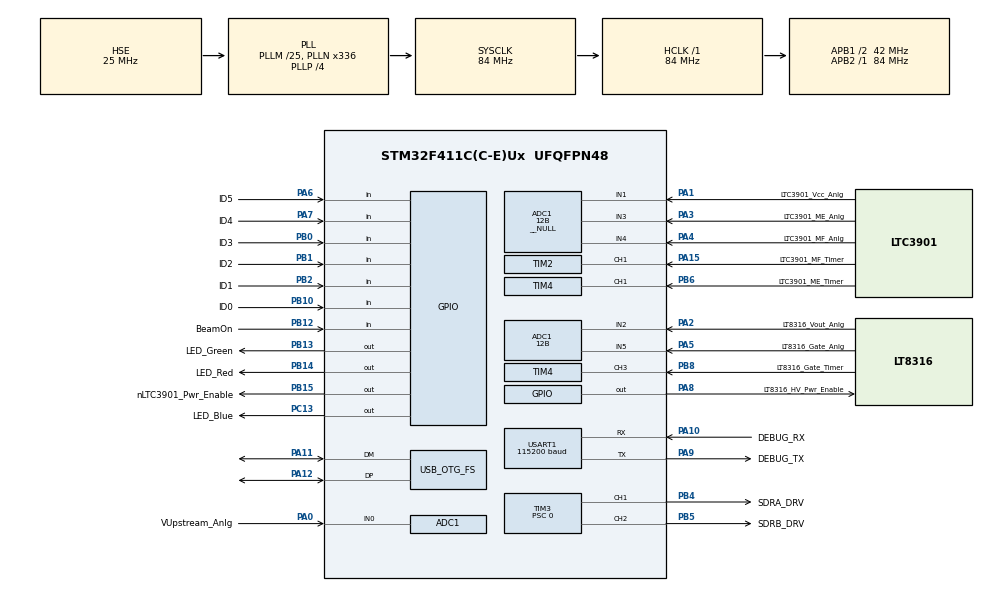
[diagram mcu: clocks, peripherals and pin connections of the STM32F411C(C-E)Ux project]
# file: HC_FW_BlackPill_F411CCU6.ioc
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ADC1.Channel-0\#ChannelRegularConversion=ADC_CHANNEL_0
ADC1.Channel-1\#ChannelRegularConversion=ADC_CHANNEL_1
ADC1.Channel-2\#ChannelRegularConversion=ADC_CHANNEL_2
ADC1.Channel-3\#ChannelRegularConversion=ADC_CHANNEL_3
ADC1.Channel-4\#ChannelRegularConversion=ADC_CHANNEL_4
ADC1.Channel-5\#ChannelRegularConversion=ADC_CHANNEL_5
ADC1.Channel-IN=ADC_CHANNEL_VREFINT
ADC1.Channel-IN0=ADC_CHANNEL_0
ADC1.Channel-IN1=ADC_CHANNEL_1
ADC1.Channel-IN2=ADC_CHANNEL_2
ADC1.Channel-IN3=ADC_CHANNEL_3
ADC1.Channel-IN4=ADC_CHANNEL_4
ADC1.Channel-IN5=ADC_CHANNEL_5
ADC1.ClockPrescaler=ADC_CLOCK_SYNC_PCLK_DIV8
ADC1.ContinuousConvMode=ENABLE
ADC1.DMAContinuousRequests=DISABLE
ADC1.DataAlign=ADC_DATAALIGN_RIGHT
ADC1.DiscontinuousConvMode=DISABLE
ADC1.EOCSelection=ADC_EOC_SEQ_CONV
ADC1.EnableAnalogWatchDog=false
ADC1.ExternalTrigConv=ADC_SOFTWARE_START
ADC1.ExternalTrigConvEdge=ADC_EXTERNALTRIGCONVEDGE_NONE
ADC1.InjNumberOfConversion=0
ADC1.Mode=__NULL
ADC1.NbrOfConversion=8
ADC1.Rank-0\#ChannelRegularConversion=1
ADC1.Rank-1\#ChannelRegularConversion=2
ADC1.Rank-2\#ChannelRegularConversion=3
ADC1.Rank-3\#ChannelRegularConversion=4
ADC1.Rank-4\#ChannelRegularConversion=5
ADC1.Rank-5\#ChannelRegularConversion=6
ADC1.Rank-6\#ChannelRegularConversion=7
ADC1.Rank-7\#ChannelRegularConversion=8
ADC1.Resolution=ADC_RESOLUTION_12B
ADC1.SamplingTime-0\#ChannelRegularConversion=ADC_SAMPLETIME_15CYCLES
ADC1.SamplingTime-1\#ChannelRegularConversion=ADC_SAMPLETIME_15CYCLES
ADC1.SamplingTime-2\#ChannelRegularConversion=ADC_SAMPLETIME_15CYCLES
ADC1.SamplingTime-3\#ChannelRegularConversion=ADC_SAMPLETIME_15CYCLES
ADC1.SamplingTime-4\#ChannelRegularConversion=ADC_SAMPLETIME_15CYCLES
ADC1.SamplingTime-5\#ChannelRegularConversion=ADC_SAMPLETIME_15CYCLES
ADC1.SamplingTime-6\#ChannelRegularConversion=ADC_SAMPLETIME_15CYCLES
ADC1.SamplingTime-7\#ChannelRegularConversion=ADC_SAMPLETIME_15CYCLES
ADC1.ScanConvMode=ENABLE
ADC1.master=1
Dma.ADC1.0.Direction=DMA_PERIPH_TO_MEMORY
Dma.ADC1.0.FIFOMode=DMA_FIFOMODE_ENABLE
Dma.ADC1.0.FIFOThreshold=DMA_FIFO_THRESHOLD_FULL
Dma.ADC1.0.Instance=DMA2_Stream0
Dma.ADC1.0.MemBurst=DMA_MBURST_SINGLE
Dma.ADC1.0.MemDataAlignment=DMA_MDATAALIGN_HALFWORD
Dma.ADC1.0.MemInc=DMA_MINC_ENABLE
Dma.ADC1.0.Mode=DMA_NORMAL
Dma.ADC1.0.PeriphBurst=DMA_PBURST_SINGLE
Dma.ADC1.0.PeriphDataAlignment=DMA_PDATAALIGN_HALFWORD
Dma.ADC1.0.PeriphInc=DMA_PINC_DISABLE
Dma.ADC1.0.Priority=DMA_PRIORITY_LOW
Dma.Request0=ADC1
Dma.Request1=TIM4_CH3
Dma.Request2=TIM4_CH1
Dma.Request3=TIM4_CH2
Dma.Request4=USART1_RX
Dma.Request5=TIM2_CH1
Dma.Request6=TIM2_CH2/CH4
Dma.TIM2_CH1.5.Direction=DMA_PERIPH_TO_MEMORY
Dma.TIM2_CH1.5.FIFOMode=DMA_FIFOMODE_ENABLE
Dma.TIM2_CH1.5.FIFOThreshold=DMA_FIFO_THRESHOLD_FULL
Dma.TIM2_CH1.5.Instance=DMA1_Stream5
Dma.TIM2_CH1.5.MemBurst=DMA_MBURST_SINGLE
Dma.TIM2_CH1.5.MemDataAlignment=DMA_MDATAALIGN_WORD
Dma.TIM2_CH1.5.MemInc=DMA_MINC_ENABLE
Dma.TIM2_CH1.5.Mode=DMA_NORMAL
Dma.TIM2_CH1.5.PeriphBurst=DMA_PBURST_SINGLE
Dma.TIM2_CH1.5.PeriphDataAlignment=DMA_PDATAALIGN_WORD
Dma.TIM2_CH1.5.PeriphInc=DMA_PINC_DISABLE
Dma.TIM2_CH1.5.Priority=DMA_PRIORITY_LOW
Dma.TIM2_CH2/CH4.6.Direction=DMA_PERIPH_TO_MEMORY
Dma.TIM2_CH2/CH4.6.FIFOMode=DMA_FIFOMODE_ENABLE
Dma.TIM2_CH2/CH4.6.FIFOThreshold=DMA_FIFO_THRESHOLD_FULL
Dma.TIM2_CH2/CH4.6.Instance=DMA1_Stream6
Dma.TIM2_CH2/CH4.6.MemBurst=DMA_MBURST_SINGLE
Dma.TIM2_CH2/CH4.6.MemDataAlignment=DMA_MDATAALIGN_WORD
Dma.TIM2_CH2/CH4.6.MemInc=DMA_MINC_ENABLE
Dma.TIM2_CH2/CH4.6.Mode=DMA_NORMAL
Dma.TIM2_CH2/CH4.6.PeriphBurst=DMA_PBURST_SINGLE
Dma.TIM2_CH2/CH4.6.PeriphDataAlignment=DMA_PDATAALIGN_WORD
Dma.TIM2_CH2/CH4.6.PeriphInc=DMA_PINC_DISABLE
Dma.TIM2_CH2/CH4.6.Priority=DMA_PRIORITY_LOW
Dma.TIM4_CH1.2.Direction=DMA_PERIPH_TO_MEMORY
Dma.TIM4_CH1.2.FIFOMode=DMA_FIFOMODE_ENABLE
Dma.TIM4_CH1.2.FIFOThreshold=DMA_FIFO_THRESHOLD_FULL
Dma.TIM4_CH1.2.Instance=DMA1_Stream0
Dma.TIM4_CH1.2.MemBurst=DMA_MBURST_SINGLE
Dma.TIM4_CH1.2.MemDataAlignment=DMA_MDATAALIGN_HALFWORD
Dma.TIM4_CH1.2.MemInc=DMA_MINC_ENABLE
Dma.TIM4_CH1.2.Mode=DMA_NORMAL
Dma.TIM4_CH1.2.PeriphBurst=DMA_PBURST_SINGLE
Dma.TIM4_CH1.2.PeriphDataAlignment=DMA_PDATAALIGN_HALFWORD
Dma.TIM4_CH1.2.PeriphInc=DMA_PINC_DISABLE
Dma.TIM4_CH1.2.Priority=DMA_PRIORITY_LOW
Dma.TIM4_CH2.3.Direction=DMA_PERIPH_TO_MEMORY
Dma.TIM4_CH2.3.FIFOMode=DMA_FIFOMODE_ENABLE
Dma.TIM4_CH2.3.FIFOThreshold=DMA_FIFO_THRESHOLD_FULL
Dma.TIM4_CH2.3.Instance=DMA1_Stream3
Dma.TIM4_CH2.3.MemBurst=DMA_MBURST_SINGLE
Dma.TIM4_CH2.3.MemDataAlignment=DMA_MDATAALIGN_HALFWORD
Dma.TIM4_CH2.3.MemInc=DMA_MINC_ENABLE
Dma.TIM4_CH2.3.Mode=DMA_NORMAL
Dma.TIM4_CH2.3.PeriphBurst=DMA_PBURST_SINGLE
Dma.TIM4_CH2.3.PeriphDataAlignment=DMA_PDATAALIGN_HALFWORD
Dma.TIM4_CH2.3.PeriphInc=DMA_PINC_DISABLE
Dma.TIM4_CH2.3.Priority=DMA_PRIORITY_LOW
Dma.TIM4_CH3.1.Direction=DMA_PERIPH_TO_MEMORY
Dma.TIM4_CH3.1.FIFOMode=DMA_FIFOMODE_ENABLE
Dma.TIM4_CH3.1.FIFOThreshold=DMA_FIFO_THRESHOLD_FULL
Dma.TIM4_CH3.1.Instance=DMA1_Stream7
Dma.TIM4_CH3.1.MemBurst=DMA_MBURST_SINGLE
Dma.TIM4_CH3.1.MemDataAlignment=DMA_MDATAALIGN_HALFWORD
Dma.TIM4_CH3.1.MemInc=DMA_MINC_ENABLE
Dma.TIM4_CH3.1.Mode=DMA_NORMAL
Dma.TIM4_CH3.1.PeriphBurst=DMA_PBURST_SINGLE
Dma.TIM4_CH3.1.PeriphDataAlignment=DMA_PDATAALIGN_HALFWORD
Dma.TIM4_CH3.1.PeriphInc=DMA_PINC_DISABLE
Dma.TIM4_CH3.1.Priority=DMA_PRIORITY_LOW
Dma.USART1_RX.4.Direction=DMA_PERIPH_TO_MEMORY
Dma.USART1_RX.4.FIFOMode=DMA_FIFOMODE_DISABLE
Dma.USART1_RX.4.Instance=DMA2_Stream2
Dma.USART1_RX.4.MemDataAlignment=DMA_MDATAALIGN_BYTE
Dma.USART1_RX.4.MemInc=DMA_MINC_ENABLE
Dma.USART1_RX.4.Mode=DMA_CIRCULAR
Dma.USART1_RX.4.PeriphDataAlignment=DMA_PDATAALIGN_BYTE
Dma.USART1_RX.4.PeriphInc=DMA_PINC_DISABLE
Dma.USART1_RX.4.Priority=DMA_PRIORITY_LOW
Mcu.Family=STM32F4
Mcu.Name=STM32F411C(C-E)Ux
Mcu.Package=UFQFPN48
NVIC.DMA1_Stream0_IRQn=true\:0\:0\:false\:false\:true\:false\:true\:true
NVIC.DMA1_Stream3_IRQn=true\:0\:0\:false\:false\:true\:false\:true\:true
NVIC.DMA1_Stream5_IRQn=true\:0\:0\:false\:false\:true\:false\:true\:true
NVIC.DMA1_Stream6_IRQn=true\:0\:0\:false\:false\:true\:false\:true\:true
NVIC.DMA1_Stream7_IRQn=true\:0\:0\:false\:false\:true\:false\:true\:true
NVIC.DMA2_Stream0_IRQn=true\:0\:0\:false\:false\:true\:false\:true\:true
NVIC.DMA2_Stream2_IRQn=true\:0\:0\:false\:false\:true\:false\:true\:true
NVIC.OTG_FS_IRQn=true\:0\:0\:false\:false\:true\:false\:true\:true
NVIC.PriorityGroup=NVIC_PRIORITYGROUP_4
NVIC.USART1_IRQn=true\:0\:0\:false\:false\:true\:true\:true\:true
PA0-WKUP.GPIO_Label=VUpstream_Anlg
PA0-WKUP.Signal=ADCx_IN0
PA1.GPIO_Label=LTC3901_Vcc_Anlg
PA1.Signal=ADCx_IN1
PA10.GPIO_Label=DEBUG_RX
PA10.Mode=Asynchronous
PA10.Signal=USART1_RX
PA11.Mode=Device_Only
PA11.Signal=USB_OTG_FS_DM
PA12.Mode=Device_Only
PA12.Signal=USB_OTG_FS_DP
PA13.Mode=Serial_Wire
PA13.Signal=SYS_JTMS-SWDIO
PA14.Mode=Serial_Wire
PA14.Signal=SYS_JTCK-SWCLK
PA15.GPIO_Label=LTC3901_MF_Timer
PA15.Signal=S_TIM2_CH1_ETR
PA2.GPIO_Label=LT8316_Vout_Anlg
PA2.Signal=ADCx_IN2
PA3.GPIO_Label=LTC3901_ME_Anlg
PA3.Signal=ADCx_IN3
PA4.GPIO_Label=LTC3901_MF_Anlg
PA4.Signal=ADCx_IN4
PA5.GPIO_Label=LT8316_Gate_Anlg
PA5.Signal=ADCx_IN5
PA6.GPIO_Label=ID5
PA6.Signal=GPIO_Input
PA7.GPIO_Label=ID4
PA7.Signal=GPIO_Input
PA8.GPIO_Label=LT8316_HV_Pwr_Enable
PA8.PinState=GPIO_PIN_RESET
PA8.Signal=GPIO_Output
PA9.GPIO_Label=DEBUG_TX
PA9.Mode=Asynchronous
PA9.Signal=USART1_TX
PB0.GPIO_Label=ID3
PB0.Signal=GPIO_Input
PB1.GPIO_Label=ID2
PB1.Signal=GPIO_Input
PB10.GPIO_Label=ID0
PB10.Signal=GPIO_Input
PB12.GPIO_Label=BeamOn
PB12.GPIO_PuPd=GPIO_PULLDOWN
PB12.Signal=GPIO_Input
PB13.GPIO_Label=LED_Green
PB13.PinState=GPIO_PIN_SET
PB13.Signal=GPIO_Output
PB14.GPIO_Label=LED_Red
PB14.PinState=GPIO_PIN_SET
PB14.Signal=GPIO_Output
PB15.GPIO_Label=nLTC3901_Pwr_Enable
PB15.PinState=GPIO_PIN_SET
PB15.Signal=GPIO_Output
PB2.GPIO_Label=ID1
PB2.Signal=GPIO_Input
PB4.GPIO_Label=SDRA_DRV
PB4.GPIO_Speed=GPIO_SPEED_FREQ_VERY_HIGH
PB4.Signal=S_TIM3_CH1
PB5.GPIO_Label=SDRB_DRV
PB5.Signal=S_TIM3_CH2
PB6.GPIO_Label=LTC3901_ME_Timer
PB6.Signal=S_TIM4_CH1
PB8.GPIO_Label=LT8316_Gate_Timer
PB8.Signal=S_TIM4_CH3
PC13-ANTI_TAMP.GPIO_Label=LED_Blue
PC13-ANTI_TAMP.PinState=GPIO_PIN_SET
PC13-ANTI_TAMP.Signal=GPIO_Output
PC14-OSC32_IN.Mode=LSE-External-Oscillator
PC14-OSC32_IN.Signal=RCC_OSC32_IN
PC15-OSC32_OUT.Mode=LSE-External-Oscillator
PC15-OSC32_OUT.Signal=RCC_OSC32_OUT
PH0\ -\ OSC_IN.Mode=HSE-External-Oscillator
PH0\ -\ OSC_IN.Signal=RCC_OSC_IN
PH1\ -\ OSC_OUT.Mode=HSE-External-Oscillator
PH1\ -\ OSC_OUT.Signal=RCC_OSC_OUT
ProjectManager.HeapSize=0x200
ProjectManager.StackSize=0x400
ProjectManager.TargetToolchain=CMake
RCC.48MHZClocksFreq_Value=48000000
RCC.AHBFreq_Value=84000000
RCC.APB1CLKDivider=RCC_HCLK_DIV2
RCC.APB1Freq_Value=42000000
RCC.APB1TimFreq_Value=84000000
RCC.APB2Freq_Value=84000000
RCC.APB2TimFreq_Value=84000000
RCC.CortexFreq_Value=84000000
RCC.FLatency=FLASH_LATENCY_2
RCC.HCLKFreq_Value=84000000
RCC.HSE_VALUE=25000000
RCC.HSI_VALUE=16000000
RCC.PLLM=25
RCC.PLLN=336
RCC.PLLP=RCC_PLLP_DIV4
RCC.PLLQ=7
RCC.PWR_Regulator_Voltage_Scale=PWR_REGULATOR_VOLTAGE_SCALE2
RCC.SYSCLKFreq_VALUE=84000000
RCC.SYSCLKSource=RCC_SYSCLKSOURCE_PLLCLK
RCC.VCOOutputFreq_Value=336000000
RTC.AsynchPrediv=127
RTC.Date=2
RTC.DayLightSaving=RTC_DAYLIGHTSAVING_NONE
RTC.Format=RTC_FORMAT_BIN
RTC.HourFormat=RTC_HOURFORMAT_24
RTC.Hours=5
RTC.Minutes=17
RTC.Month=RTC_MONTH_MAY
RTC.Seconds=0
RTC.StoreOperation=RTC_STOREOPERATION_RESET
RTC.SynchPrediv=255
RTC.WeekDay=RTC_WEEKDAY_SATURDAY
RTC.Year=0
SH.ADCx_IN0.0=ADC1_IN0,IN0
SH.ADCx_IN1.0=ADC1_IN1,IN1
SH.ADCx_IN2.0=ADC1_IN2,IN2
SH.ADCx_IN3.0=ADC1_IN3,IN3
SH.ADCx_IN4.0=ADC1_IN4,IN4
SH.ADCx_IN5.0=ADC1_IN5,IN5
SH.S_TIM2_CH1_ETR.0=TIM2_CH1,Input_Capture1_from_TI1
SH.S_TIM3_CH1.0=TIM3_CH1,Output Compare1 CH1
SH.S_TIM3_CH2.0=TIM3_CH2,Output Compare2 CH2
SH.S_TIM4_CH1.0=TIM4_CH1,Input_Capture1_from_TI1
SH.S_TIM4_CH3.0=TIM4_CH3,Input_Capture3_from_TI3
TIM2.AutoReloadPreload=TIM_AUTORELOAD_PRELOAD_DISABLE
TIM2.Channel-Input_Capture1_from_TI1=TIM_CHANNEL_1
TIM2.Channel-Input_Capture2_from_TI1_63=TIM_CHANNEL_2
TIM2.ClockDivision=TIM_CLOCKDIVISION_DIV1
TIM2.CounterMode=TIM_COUNTERMODE_UP
TIM2.ICFilter_CH1=0
TIM2.ICPolarity_CH1=TIM_INPUTCHANNELPOLARITY_RISING
TIM2.ICPolarity_CH2=TIM_INPUTCHANNELPOLARITY_FALLING
TIM2.ICPrescaler-Input_Capture1_from_TI1=TIM_ICPSC_DIV1
TIM2.ICPrescaler-Input_Capture2_from_TI1_63=TIM_ICPSC_DIV1
TIM2.ICSelection-Input_Capture1_from_TI1=TIM_ICSELECTION_DIRECTTI
TIM2.ICSelection-Input_Capture2_from_TI1_63=TIM_ICSELECTION_INDIRECTTI
TIM2.Period=4294967295
TIM2.Prescaler=7
TIM2.TIM_MasterOutputTrigger=TIM_TRGO_RESET
TIM2.TIM_MasterSlaveMode=TIM_MASTERSLAVEMODE_DISABLE
TIM3.AutoReloadPreload=TIM_AUTORELOAD_PRELOAD_ENABLE
TIM3.Channel-Output\ Compare1\ CH1=TIM_CHANNEL_1
TIM3.Channel-Output\ Compare2\ CH2=TIM_CHANNEL_2
TIM3.ClockDivision=TIM_CLOCKDIVISION_DIV1
TIM3.CounterMode=TIM_COUNTERMODE_UP
TIM3.OC1Preload=ENABLE
TIM3.OC2Preload=ENABLE
TIM3.OCMode_1=TIM_OCMODE_TOGGLE
TIM3.OCMode_2=TIM_OCMODE_TOGGLE
TIM3.OCPolarity_1=TIM_OCPOLARITY_HIGH
TIM3.OCPolarity_2=TIM_OCPOLARITY_HIGH
TIM3.Period=167
TIM3.Prescaler=0
TIM3.Pulse-Output\ Compare1\ CH1=0
TIM3.Pulse-Output\ Compare2\ CH2=83
TIM3.TIM_MasterOutputTrigger=TIM_TRGO_RESET
TIM3.TIM_MasterSlaveMode=TIM_MASTERSLAVEMODE_DISABLE
TIM4.AutoReloadPreload=TIM_AUTORELOAD_PRELOAD_DISABLE
TIM4.Channel-Input_Capture1_from_TI1=TIM_CHANNEL_1
TIM4.Channel-Input_Capture2_from_TI1_63=TIM_CHANNEL_2
TIM4.Channel-Input_Capture3_from_TI3=TIM_CHANNEL_3
TIM4.Channel-Input_Capture4_from_TI3_63=TIM_CHANNEL_4
TIM4.ClockDivision=TIM_CLOCKDIVISION_DIV1
TIM4.CounterMode=TIM_COUNTERMODE_UP
TIM4.ICFilter_CH1=0
TIM4.ICFilter_CH3=0
TIM4.ICPolarity_CH1=TIM_INPUTCHANNELPOLARITY_RISING
TIM4.ICPolarity_CH2=TIM_INPUTCHANNELPOLARITY_FALLING
TIM4.ICPolarity_CH3=TIM_INPUTCHANNELPOLARITY_RISING
TIM4.ICPolarity_CH4=TIM_INPUTCHANNELPOLARITY_FALLING
TIM4.ICPrescaler-Input_Capture1_from_TI1=TIM_ICPSC_DIV1
TIM4.ICPrescaler-Input_Capture2_from_TI1_63=TIM_ICPSC_DIV1
TIM4.ICPrescaler-Input_Capture3_from_TI3=TIM_ICPSC_DIV1
TIM4.ICPrescaler-Input_Capture4_from_TI3_63=TIM_ICPSC_DIV1
TIM4.ICSelection-Input_Capture1_from_TI1=TIM_ICSELECTION_DIRECTTI
TIM4.ICSelection-Input_Capture2_from_TI1_63=TIM_ICSELECTION_INDIRECTTI
TIM4.ICSelection-Input_Capture3_from_TI3=TIM_ICSELECTION_DIRECTTI
TIM4.ICSelection-Input_Capture4_from_TI3_63=TIM_ICSELECTION_INDIRECTTI
TIM4.Period=65535
TIM4.Prescaler=7
TIM4.TIM_MasterOutputTrigger=TIM_TRGO_RESET
TIM4.TIM_MasterSlaveMode=TIM_MASTERSLAVEMODE_DISABLE
TIM5.AutoReloadPreload=TIM_AUTORELOAD_PRELOAD_DISABLE
TIM5.ClockDivision=TIM_CLOCKDIVISION_DIV1
TIM5.CounterMode=TIM_COUNTERMODE_UP
TIM5.Period=4294967295
TIM5.Prescaler=0
TIM5.TIM_MasterOutputTrigger=TIM_TRGO_RESET
TIM5.TIM_MasterSlaveMode=TIM_MASTERSLAVEMODE_DISABLE
USART1.BaudRate=115200
USART1.Mode=MODE_TX_RX
USART1.OverSampling=UART_OVERSAMPLING_16
USART1.Parity=PARITY_NONE
USART1.StopBits=STOPBITS_1
USART1.VirtualMode=VM_ASYNC
USART1.WordLength=WORDLENGTH_8B
USB_DEVICE.APP_RX_DATA_SIZE=1024
USB_DEVICE.APP_TX_DATA_SIZE=1024
USB_DEVICE.CLASS_NAME_FS=CDC
USB_DEVICE.CONFIGURATION_STRING_CDC_FS=CDC Config
USB_DEVICE.INTERFACE_STRING_CDC_FS=CDC Interface
USB_DEVICE.LANGID_STRING=1033
USB_DEVICE.MANUFACTURER_STRING=STMicroelectronics
USB_DEVICE.PID_CDC_FS=22336
USB_DEVICE.PRODUCT_STRING_CDC_FS=STM32 Virtual ComPort
USB_DEVICE.USBD_DEBUG_LEVEL=0
USB_DEVICE.USBD_MAX_NUM_CONFIGURATION=1
USB_DEVICE.USBD_MAX_NUM_INTERFACES=1
USB_DEVICE.USBD_MAX_STR_DESC_SIZ=512
USB_DEVICE.USBD_SELF_POWERED=1
USB_DEVICE.VID=1155
USB_DEVICE.VirtualMode=Cdc
USB_DEVICE.VirtualModeFS=Cdc_FS
USB_OTG_FS.Sof_enable=DISABLE
USB_OTG_FS.VirtualMode=Device_Only
USB_OTG_FS.low_power_enable=DISABLE
USB_OTG_FS.lpm_enable=DISABLE
USB_OTG_FS.vbus_sensing_enable=DISABLE
VP_ADC1_TempSens_Input.Mode=IN-TempSens
VP_ADC1_Vref_Input.Mode=IN-Vrefint
VP_RTC_VS_RTC_Activate.Mode=RTC_Enabled
VP_RTC_VS_RTC_Calendar.Mode=RTC_Calendar
VP_TIM2_VS_ClockSourceINT.Mode=Internal
VP_TIM2_VS_indirect_ch1.Mode=Input_Capture2_from_TI1_63
VP_TIM3_VS_ClockSourceINT.Mode=Internal
VP_TIM4_VS_indirect_ch1.Mode=Input_Capture2_from_TI1_63
VP_TIM4_VS_indirect_ch3.Mode=Input_Capture4_from_TI3_63
VP_TIM5_VS_ClockSourceINT.Mode=Internal
VP_USB_DEVICE_VS_USB_DEVICE_CDC_FS.Mode=CDC_FS
board=custom

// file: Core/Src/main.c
/* USER CODE BEGIN Header */
/**
  ******************************************************************************
  * @file           : main.c
  * @brief          : Main program body
  ******************************************************************************
  * @attention
  *
  * Copyright (c) 2026 STMicroelectronics.
  * All rights reserved.
  *
  * This software is licensed under terms that can be found in the LICENSE file
  * in the root directory of this software component.
  * If no LICENSE file comes with this software, it is provided AS-IS.
  *
  ******************************************************************************
  */
/* USER CODE END Header */
#include "main.h"
#include "adc.h"
#include "dma.h"
#include "rtc.h"
#include "tim.h"
#include "usart.h"
#include "usb_device.h"
#include "gpio.h"

/* USER CODE BEGIN Includes */
#include "fw_app.h"
#include "reset_reason_drv.h"
#include "usbd_cdc_if.h"
/* USER CODE END Includes */

void SystemClock_Config(void);

int main(void)
{

  /* MCU Configuration--------------------------------------------------------*/

  /* Reset of all peripherals, Initializes the Flash interface and the Systick. */
  HAL_Init();

  /* USER CODE BEGIN Init */
  reset_reason_drv_init();

  /* USER CODE END Init */

  /* Configure the system clock */
  SystemClock_Config();

  /* Initialize all configured peripherals */
  MX_GPIO_Init();
  MX_DMA_Init();
  MX_ADC1_Init();
  MX_TIM2_Init();
  MX_TIM3_Init();
  MX_TIM4_Init();
  MX_USART1_UART_Init();
  MX_USB_DEVICE_Init();
  MX_TIM5_Init();
  MX_RTC_Init();
  /* USER CODE BEGIN 2 */
  fw_app_init();

//  sync_drv_enable();

//  sync_drv_configure_and_enable(&sync_cfg);

//  HAL_TIM_OC_Start(&htim3, TIM_CHANNEL_1);
//  HAL_TIM_OC_MspInit(&htim3);

/* Test Code toggles SDRA pin (but only when it's been configured as GPIO)
  static uint32_t s_last_toggle_ms;
  while (1) {
    uint32_t now_ms = HAL_GetTick();

    if ((now_ms - s_last_toggle_ms) >= 1U)
    {
        s_last_toggle_ms = now_ms;
        HAL_GPIO_TogglePin(SDRA_DRV_GPIO_Port, SDRA_DRV_Pin);
    }
  } // */

  /* USER CODE END 2 */

  /* Infinite loop */
  while (1)
  {

    /* USER CODE BEGIN 3 */
    fw_app_run();
  }
  /* USER CODE END 3 */
}

void SystemClock_Config(void)
{
  RCC_OscInitTypeDef RCC_OscInitStruct = {0};
  RCC_ClkInitTypeDef RCC_ClkInitStruct = {0};

  /** Configure the main internal regulator output voltage
  */
  __HAL_RCC_PWR_CLK_ENABLE();
  __HAL_PWR_VOLTAGESCALING_CONFIG(PWR_REGULATOR_VOLTAGE_SCALE2);

  /** Initializes the RCC Oscillators according to the specified parameters
  * in the RCC_OscInitTypeDef structure.
  */
  RCC_OscInitStruct.OscillatorType = RCC_OSCILLATORTYPE_LSI|RCC_OSCILLATORTYPE_HSE;
  RCC_OscInitStruct.HSEState = RCC_HSE_ON;
  RCC_OscInitStruct.LSIState = RCC_LSI_ON;
  RCC_OscInitStruct.PLL.PLLState = RCC_PLL_ON;
  RCC_OscInitStruct.PLL.PLLSource = RCC_PLLSOURCE_HSE;
  RCC_OscInitStruct.PLL.PLLM = 25;
  RCC_OscInitStruct.PLL.PLLN = 336;
  RCC_OscInitStruct.PLL.PLLP = RCC_PLLP_DIV4;
  RCC_OscInitStruct.PLL.PLLQ = 7;
  if (HAL_RCC_OscConfig(&RCC_OscInitStruct) != HAL_OK)
  {
    Error_Handler();
  }

  /** Initializes the CPU, AHB and APB buses clocks
  */
  RCC_ClkInitStruct.ClockType = RCC_CLOCKTYPE_HCLK|RCC_CLOCKTYPE_SYSCLK
                              |RCC_CLOCKTYPE_PCLK1|RCC_CLOCKTYPE_PCLK2;
  RCC_ClkInitStruct.SYSCLKSource = RCC_SYSCLKSOURCE_PLLCLK;
  RCC_ClkInitStruct.AHBCLKDivider = RCC_SYSCLK_DIV1;
  RCC_ClkInitStruct.APB1CLKDivider = RCC_HCLK_DIV2;
  RCC_ClkInitStruct.APB2CLKDivider = RCC_HCLK_DIV1;

  if (HAL_RCC_ClockConfig(&RCC_ClkInitStruct, FLASH_LATENCY_2) != HAL_OK)
  {
    Error_Handler();
  }
}

void Error_Handler(void)
{
  __disable_irq();
  while (1)
  {
  }
}
